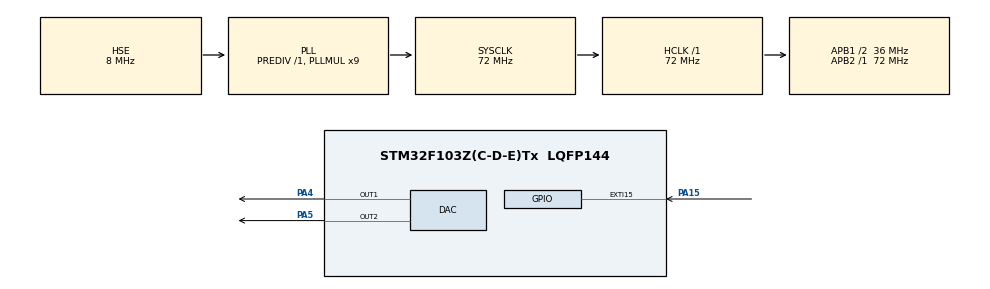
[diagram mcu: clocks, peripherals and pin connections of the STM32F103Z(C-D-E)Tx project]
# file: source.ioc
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DAC.DAC_OutputBuffer=DAC_OUTPUTBUFFER_DISABLE
DAC.DAC_Trigger=DAC_TRIGGER_T2_TRGO
Dma.DAC_CH1.1.Direction=DMA_MEMORY_TO_PERIPH
Dma.DAC_CH1.1.Instance=DMA2_Channel3
Dma.DAC_CH1.1.MemDataAlignment=DMA_MDATAALIGN_HALFWORD
Dma.DAC_CH1.1.MemInc=DMA_MINC_ENABLE
Dma.DAC_CH1.1.Mode=DMA_CIRCULAR
Dma.DAC_CH1.1.PeriphDataAlignment=DMA_PDATAALIGN_HALFWORD
Dma.DAC_CH1.1.PeriphInc=DMA_PINC_DISABLE
Dma.DAC_CH1.1.Priority=DMA_PRIORITY_LOW
Dma.Request0=TIM2_UP
Dma.Request1=DAC_CH1
Dma.TIM2_UP.0.Direction=DMA_PERIPH_TO_MEMORY
Dma.TIM2_UP.0.Instance=DMA1_Channel2
Dma.TIM2_UP.0.MemDataAlignment=DMA_MDATAALIGN_HALFWORD
Dma.TIM2_UP.0.MemInc=DMA_MINC_ENABLE
Dma.TIM2_UP.0.Mode=DMA_CIRCULAR
Dma.TIM2_UP.0.PeriphDataAlignment=DMA_PDATAALIGN_HALFWORD
Dma.TIM2_UP.0.PeriphInc=DMA_PINC_DISABLE
Dma.TIM2_UP.0.Priority=DMA_PRIORITY_LOW
Mcu.Family=STM32F1
Mcu.Name=STM32F103Z(C-D-E)Tx
Mcu.Package=LQFP144
NVIC.DMA1_Channel2_IRQn=true\:0\:0\:false\:false\:true\:false\:true
NVIC.DMA2_Channel3_IRQn=true\:0\:0\:false\:false\:true\:false\:true
NVIC.EXTI15_10_IRQn=true\:0\:0\:false\:false\:true\:true\:true
NVIC.PriorityGroup=NVIC_PRIORITYGROUP_4
NVIC.TIM3_IRQn=true\:0\:0\:false\:false\:true\:true\:true
OSC_IN.Mode=HSE-External-Oscillator
OSC_IN.Signal=RCC_OSC_IN
OSC_OUT.Mode=HSE-External-Oscillator
OSC_OUT.Signal=RCC_OSC_OUT
PA13.Mode=Serial_Wire
PA13.Signal=SYS_JTMS-SWDIO
PA14.Mode=Serial_Wire
PA14.Signal=SYS_JTCK-SWCLK
PA15.GPIO_ModeDefaultEXTI=GPIO_MODE_IT_FALLING
PA15.Signal=GPXTI15
PA4.Signal=COMP_DAC1_group
PA5.Signal=COMP_DAC2_group
ProjectManager.HeapSize=0x200
ProjectManager.StackSize=0x400
ProjectManager.TargetToolchain=MDK-ARM V5
RCC.AHBFreq_Value=72000000
RCC.APB1CLKDivider=RCC_HCLK_DIV2
RCC.APB1Freq_Value=36000000
RCC.APB1TimFreq_Value=72000000
RCC.APB2Freq_Value=72000000
RCC.APB2TimFreq_Value=72000000
RCC.HCLKFreq_Value=72000000
RCC.PLLMUL=RCC_PLL_MUL9
RCC.PLLSourceVirtual=RCC_PLLSOURCE_HSE
RCC.SYSCLKFreq_VALUE=72000000
RCC.SYSCLKSource=RCC_SYSCLKSOURCE_PLLCLK
RCC.USBFreq_Value=72000000
SH.COMP_DAC1_group.0=DAC_OUT1,DAC_OUT1
SH.COMP_DAC2_group.0=DAC_OUT2,DAC_OUT2
TIM2.AutoReloadPreload=TIM_AUTORELOAD_PRELOAD_ENABLE
TIM2.Period=2879
TIM2.Prescaler=0
TIM2.TIM_MasterOutputTrigger=TIM_TRGO_UPDATE
TIM3.AutoReloadPreload=TIM_AUTORELOAD_PRELOAD_ENABLE
TIM3.Period=899
TIM3.Prescaler=79
VP_TIM2_VS_ClockSourceINT.Mode=Internal
VP_TIM3_VS_ClockSourceINT.Mode=Internal
board=custom

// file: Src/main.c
/* USER CODE BEGIN Header */
/**
  ******************************************************************************
  * @file           : main.c
  * @brief          : Main program body
  ******************************************************************************
  * @attention
  *
  * <h2><center>&copy; Copyright (c) 2021 STMicroelectronics.
  * All rights reserved.</center></h2>
  *
  * This software component is licensed by ST under BSD 3-Clause license,
  * the "License"; You may not use this file except in compliance with the
  * License. You may obtain a copy of the License at:
  *                        opensource.org/licenses/BSD-3-Clause
  *
  ******************************************************************************
  */
/* USER CODE END Header */

#include "main.h"

DAC_HandleTypeDef hdac;
DMA_HandleTypeDef hdma_dac_ch1;

TIM_HandleTypeDef htim2;
TIM_HandleTypeDef htim3;
DMA_HandleTypeDef hdma_tim2_up;

void SystemClock_Config(void);
static void MX_GPIO_Init(void);
static void MX_DMA_Init(void);
static void MX_DAC_Init(void);
static void MX_TIM2_Init(void);
static void MX_TIM3_Init(void);

/* USER CODE BEGIN 0 */
float sin25[25]={
0.0000,0.2487,0.4818,0.6845,0.8443,0.9511,0.9980,0.9823,0.9048,0.7705,0.5878,0.3681,0.1253,-0.1253,-0.3681,-0.5878,-0.7705,-0.9048,-0.9823,-0.9980,-0.9511,-0.8443,-0.6845,-0.4818,-0.2487
};
float sin24[24]={
	0.0000,0.2588,0.5000,0.7071,0.8660,0.9659,1.0000,0.9659,0.8660,0.7071,0.5000,0.2588,0.0000,-0.2588,-0.5000,-0.7071,-0.8660,-0.9659,-1.0000,-0.9659,-0.8660,-0.7071,-0.5000,-0.2588
};
float vol=1;
uint16_t DAC_0[25]={0,0,0,0,0,0,0,0,0,0,0,0,0,0,0,0,0,0,0,0,0,0,0,0,0};
//uint16_t DAC_Buf[25]={2048,2063,2078,2090,2100,2107,2110,2109,2104,2096,2084,2071,2056,2040,2025,2012,2000,1992,1987,1986,1989,1996,2006,2018,2033};
uint16_t DAC_Buf[24];
int mid=2047;
//float max=62.06;
float max=62.0606;
int i=1,j=0;
//void HAL_TIM_PeriodElapsedCallback(TIM_HandleTypeDef *htim)
//{
//	if(htim == &htim2){
//		//HAL_DAC_SetValue(&hdac,DAC1_CHANNEL_1,DAC_ALIGN_12B_R,mid+(int)(max*sin1k[i]));
//		if(i%2==0){
//			HAL_DAC_SetValue(&hdac,DAC1_CHANNEL_1,DAC_ALIGN_12B_R,1000);
//		}
//		else{
//			HAL_DAC_SetValue(&hdac,DAC1_CHANNEL_1,DAC_ALIGN_12B_R,0);

//		}
//		i=i+1;
//		if(i>=1000){
//			i=i-1000;
//		}
//	}
//
//}
void HAL_TIM_PeriodElapsedCallback(TIM_HandleTypeDef *htim)
{
		if(htim == &htim3){
			if(i==1){
				HAL_DAC_Stop_DMA(&hdac,DAC1_CHANNEL_1);
				HAL_DAC_Start_DMA(&hdac,DAC1_CHANNEL_1,(uint32_t*)DAC_Buf,24,DAC_ALIGN_12B_R);
			}
			if(i<=40){
				HAL_DAC_SetValue(&hdac,DAC_CHANNEL_2,DAC_ALIGN_12B_R,4095*i/40);
					TIM2->ARR=72000*1.0/i/24-1;
			}

			if(i>=41){
					HAL_DAC_SetValue(&hdac,DAC_CHANNEL_2,DAC_ALIGN_12B_R,4095*(80-i)/40);
				if(i==41){
					TIM2->ARR=2879;
						HAL_DAC_Stop_DMA(&hdac,DAC1_CHANNEL_1);
						HAL_DAC_Start_DMA(&hdac,DAC1_CHANNEL_1,(uint32_t*)DAC_Buf,1,DAC_ALIGN_12B_R);
				}
			}

		i++;
		if(i>80){
			i=1;
		}
	}
}
/* USER CODE END 0 */

int main(void)
{

  /* MCU Configuration--------------------------------------------------------*/

  /* Reset of all peripherals, Initializes the Flash interface and the Systick. */
  HAL_Init();

  /* Configure the system clock */
  SystemClock_Config();

  /* Initialize all configured peripherals */
  MX_GPIO_Init();
  MX_DMA_Init();
  MX_DAC_Init();
  MX_TIM2_Init();
  MX_TIM3_Init();
  /* USER CODE BEGIN 2 */
//delay_init(180); //???????
max=vol*0.1/2/3.3*4096;
for(j=0;j<24;j++){
	DAC_Buf[j]=(uint16_t)(mid+max*sin24[j]);
}

HAL_TIM_Base_Start(&htim2);

HAL_DAC_Start(&hdac,DAC_CHANNEL_2); //??DAC??
HAL_DAC_Start_DMA(&hdac,DAC1_CHANNEL_1,(uint32_t*)DAC_Buf,24,DAC_ALIGN_12B_R);
HAL_TIM_Base_Start_IT(&htim3);

  /* USER CODE END 2 */

  /* Infinite loop */
  while (1)
  {

  }
}

void SystemClock_Config(void)
{
  RCC_OscInitTypeDef RCC_OscInitStruct = {0};
  RCC_ClkInitTypeDef RCC_ClkInitStruct = {0};

  /** Initializes the CPU, AHB and APB busses clocks
  */
  RCC_OscInitStruct.OscillatorType = RCC_OSCILLATORTYPE_HSE;
  RCC_OscInitStruct.HSEState = RCC_HSE_ON;
  RCC_OscInitStruct.HSEPredivValue = RCC_HSE_PREDIV_DIV1;
  RCC_OscInitStruct.HSIState = RCC_HSI_ON;
  RCC_OscInitStruct.PLL.PLLState = RCC_PLL_ON;
  RCC_OscInitStruct.PLL.PLLSource = RCC_PLLSOURCE_HSE;
  RCC_OscInitStruct.PLL.PLLMUL = RCC_PLL_MUL9;
  if (HAL_RCC_OscConfig(&RCC_OscInitStruct) != HAL_OK)
  {
    Error_Handler();
  }
  /** Initializes the CPU, AHB and APB busses clocks
  */
  RCC_ClkInitStruct.ClockType = RCC_CLOCKTYPE_HCLK|RCC_CLOCKTYPE_SYSCLK
                              |RCC_CLOCKTYPE_PCLK1|RCC_CLOCKTYPE_PCLK2;
  RCC_ClkInitStruct.SYSCLKSource = RCC_SYSCLKSOURCE_PLLCLK;
  RCC_ClkInitStruct.AHBCLKDivider = RCC_SYSCLK_DIV1;
  RCC_ClkInitStruct.APB1CLKDivider = RCC_HCLK_DIV2;
  RCC_ClkInitStruct.APB2CLKDivider = RCC_HCLK_DIV1;

  if (HAL_RCC_ClockConfig(&RCC_ClkInitStruct, FLASH_LATENCY_2) != HAL_OK)
  {
    Error_Handler();
  }
}

static void MX_DAC_Init(void)
{

  DAC_ChannelConfTypeDef sConfig = {0};

  /** DAC Initialization
  */
  hdac.Instance = DAC;
  if (HAL_DAC_Init(&hdac) != HAL_OK)
  {
    Error_Handler();
  }
  /** DAC channel OUT1 config
  */
  sConfig.DAC_Trigger = DAC_TRIGGER_T2_TRGO;
  sConfig.DAC_OutputBuffer = DAC_OUTPUTBUFFER_DISABLE;
  if (HAL_DAC_ConfigChannel(&hdac, &sConfig, DAC_CHANNEL_1) != HAL_OK)
  {
    Error_Handler();
  }
  /** DAC channel OUT2 config
  */
  sConfig.DAC_Trigger = DAC_TRIGGER_NONE;
  sConfig.DAC_OutputBuffer = DAC_OUTPUTBUFFER_ENABLE;
  if (HAL_DAC_ConfigChannel(&hdac, &sConfig, DAC_CHANNEL_2) != HAL_OK)
  {
    Error_Handler();
  }

}

static void MX_TIM2_Init(void)
{

  TIM_ClockConfigTypeDef sClockSourceConfig = {0};
  TIM_MasterConfigTypeDef sMasterConfig = {0};

  htim2.Instance = TIM2;
  htim2.Init.Prescaler = 0;
  htim2.Init.CounterMode = TIM_COUNTERMODE_UP;
  htim2.Init.Period = 2879;
  htim2.Init.ClockDivision = TIM_CLOCKDIVISION_DIV1;
  htim2.Init.AutoReloadPreload = TIM_AUTORELOAD_PRELOAD_ENABLE;
  if (HAL_TIM_Base_Init(&htim2) != HAL_OK)
  {
    Error_Handler();
  }
  sClockSourceConfig.ClockSource = TIM_CLOCKSOURCE_INTERNAL;
  if (HAL_TIM_ConfigClockSource(&htim2, &sClockSourceConfig) != HAL_OK)
  {
    Error_Handler();
  }
  sMasterConfig.MasterOutputTrigger = TIM_TRGO_UPDATE;
  sMasterConfig.MasterSlaveMode = TIM_MASTERSLAVEMODE_DISABLE;
  if (HAL_TIMEx_MasterConfigSynchronization(&htim2, &sMasterConfig) != HAL_OK)
  {
    Error_Handler();
  }

}

static void MX_TIM3_Init(void)
{

  TIM_ClockConfigTypeDef sClockSourceConfig = {0};
  TIM_MasterConfigTypeDef sMasterConfig = {0};

  htim3.Instance = TIM3;
  htim3.Init.Prescaler = 79;
  htim3.Init.CounterMode = TIM_COUNTERMODE_UP;
  htim3.Init.Period = 899;
  htim3.Init.ClockDivision = TIM_CLOCKDIVISION_DIV1;
  htim3.Init.AutoReloadPreload = TIM_AUTORELOAD_PRELOAD_ENABLE;
  if (HAL_TIM_Base_Init(&htim3) != HAL_OK)
  {
    Error_Handler();
  }
  sClockSourceConfig.ClockSource = TIM_CLOCKSOURCE_INTERNAL;
  if (HAL_TIM_ConfigClockSource(&htim3, &sClockSourceConfig) != HAL_OK)
  {
    Error_Handler();
  }
  sMasterConfig.MasterOutputTrigger = TIM_TRGO_RESET;
  sMasterConfig.MasterSlaveMode = TIM_MASTERSLAVEMODE_DISABLE;
  if (HAL_TIMEx_MasterConfigSynchronization(&htim3, &sMasterConfig) != HAL_OK)
  {
    Error_Handler();
  }

}

static void MX_DMA_Init(void)
{

  /* DMA controller clock enable */
  __HAL_RCC_DMA1_CLK_ENABLE();
  __HAL_RCC_DMA2_CLK_ENABLE();

  /* DMA interrupt init */
  /* DMA1_Channel2_IRQn interrupt configuration */
  HAL_NVIC_SetPriority(DMA1_Channel2_IRQn, 0, 0);
  HAL_NVIC_EnableIRQ(DMA1_Channel2_IRQn);
  /* DMA2_Channel3_IRQn interrupt configuration */
  HAL_NVIC_SetPriority(DMA2_Channel3_IRQn, 0, 0);
  HAL_NVIC_EnableIRQ(DMA2_Channel3_IRQn);

}

static void MX_GPIO_Init(void)
{
  GPIO_InitTypeDef GPIO_InitStruct = {0};

  /* GPIO Ports Clock Enable */
  __HAL_RCC_GPIOA_CLK_ENABLE();

  /*Configure GPIO pin : PA15 */
  GPIO_InitStruct.Pin = GPIO_PIN_15;
  GPIO_InitStruct.Mode = GPIO_MODE_IT_FALLING;
  GPIO_InitStruct.Pull = GPIO_NOPULL;
  HAL_GPIO_Init(GPIOA, &GPIO_InitStruct);

  /* EXTI interrupt init*/
  HAL_NVIC_SetPriority(EXTI15_10_IRQn, 0, 0);
  HAL_NVIC_EnableIRQ(EXTI15_10_IRQn);

}

/* USER CODE BEGIN 4 */
void HAL_GPIO_EXTI_Callback(uint16_t GPIO_Pin){
	if(GPIO_Pin==GPIO_PIN_15){
		HAL_TIM_Base_Stop_IT(&htim3);
		HAL_TIM_Base_Stop_IT(&htim2);
		HAL_DAC_Stop_DMA(&hdac,DAC1_CHANNEL_1);

		vol+=1;
		max=vol*0.1/2/3.3*4096;
		for(j=0;j<24;j++){
			DAC_Buf[j]=(uint16_t)(mid+max*sin24[j]);
		}
		if(vol>20){vol=1;}

		HAL_TIM_Base_Start_IT(&htim3);
		HAL_TIM_Base_Start_IT(&htim2);
		HAL_DAC_Start_DMA(&hdac,DAC1_CHANNEL_1,(uint32_t*)DAC_Buf,24,DAC_ALIGN_12B_R);

	}
}
/* USER CODE END 4 */

void Error_Handler(void)
{
}

/************************ (C) COPYRIGHT STMicroelectronics *****END OF FILE****/
